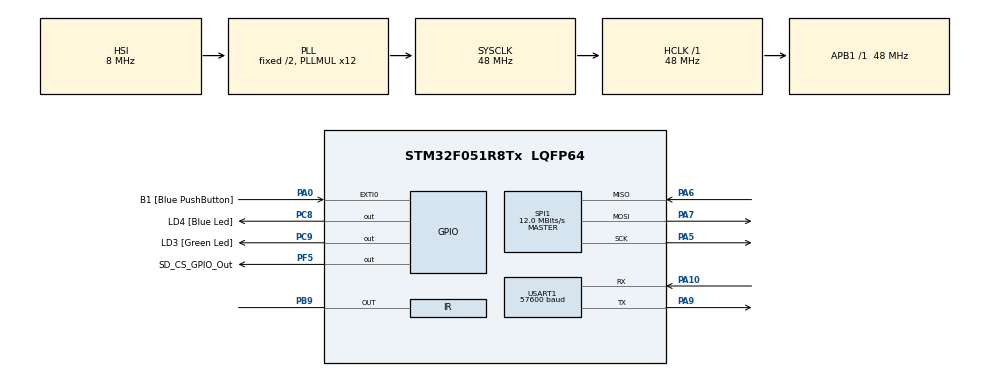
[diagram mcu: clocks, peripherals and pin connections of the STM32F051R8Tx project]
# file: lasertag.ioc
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Dma.Request0=USART1_RX
Dma.Request1=USART1_TX
Dma.USART1_RX.0.DMA_Remap=DMA_REMAP_USART1_RX_DMA_CH5
Dma.USART1_RX.0.Direction=DMA_PERIPH_TO_MEMORY
Dma.USART1_RX.0.Instance=DMA1_Channel5
Dma.USART1_RX.0.MemDataAlignment=DMA_MDATAALIGN_BYTE
Dma.USART1_RX.0.MemInc=DMA_MINC_ENABLE
Dma.USART1_RX.0.Mode=DMA_CIRCULAR
Dma.USART1_RX.0.PeriphDataAlignment=DMA_PDATAALIGN_BYTE
Dma.USART1_RX.0.PeriphInc=DMA_PINC_DISABLE
Dma.USART1_RX.0.Priority=DMA_PRIORITY_HIGH
Dma.USART1_TX.1.DMA_Remap=DMA_REMAP_USART1_TX_DMA_CH4
Dma.USART1_TX.1.Direction=DMA_MEMORY_TO_PERIPH
Dma.USART1_TX.1.Instance=DMA1_Channel4
Dma.USART1_TX.1.MemDataAlignment=DMA_MDATAALIGN_BYTE
Dma.USART1_TX.1.MemInc=DMA_MINC_ENABLE
Dma.USART1_TX.1.Mode=DMA_NORMAL
Dma.USART1_TX.1.PeriphDataAlignment=DMA_PDATAALIGN_BYTE
Dma.USART1_TX.1.PeriphInc=DMA_PINC_DISABLE
Dma.USART1_TX.1.Priority=DMA_PRIORITY_HIGH
FREERTOS.Tasks01=defaultTask,0,128,StartDefaultTask,Default
Mcu.Family=STM32F0
Mcu.Name=STM32F051R8Tx
Mcu.Package=LQFP64
NVIC.DMA1_Channel4_5_IRQn=true\:3\:0\:false\:false\:true
NVIC.SPI1_IRQn=true\:3\:0\:false\:false\:true
NVIC.TIM6_DAC_IRQn=true\:0\:0\:false\:false\:true
NVIC.TimeBase=TIM6_DAC_IRQn
NVIC.TimeBaseIP=TIM6
NVIC.USART1_IRQn=true\:3\:0\:false\:false\:true
PA0.GPIO_Label=B1 [Blue PushButton]
PA0.GPIO_ModeDefaultEXTI=GPIO_MODE_EVT_RISING
PA0.Signal=GPXTI0
PA10.Mode=Asynchronous
PA10.Signal=USART1_RX
PA13.GPIO_Label=SWDIO
PA13.Signal=SYS_SWDIO
PA14.GPIO_Label=SWCLK
PA14.Signal=SYS_SWCLK
PA5.Mode=Full_Duplex_Master
PA5.Signal=SPI1_SCK
PA6.Mode=Full_Duplex_Master
PA6.Signal=SPI1_MISO
PA7.Mode=Full_Duplex_Master
PA7.Signal=SPI1_MOSI
PA9.Mode=Asynchronous
PA9.Signal=USART1_TX
PB9.Mode=INFRARED
PB9.Signal=IR_OUT
PC8.GPIO_Label=LD4 [Blue Led]
PC8.Signal=GPIO_Output
PC9.GPIO_Label=LD3 [Green Led]
PC9.Signal=GPIO_Output
PF5.GPIO_Label=SD_CS_GPIO_Out
PF5.Signal=GPIO_Output
ProjectManager.HeapSize=0x200
ProjectManager.StackSize=0x400
ProjectManager.TargetToolchain=MDK-ARM V5
RCC.AHBFreq_Value=48000000
RCC.APB1Freq_Value=48000000
RCC.APB1TimFreq_Value=48000000
RCC.HCLKFreq_Value=48000000
RCC.PLLMUL=RCC_PLL_MUL12
RCC.SYSCLKFreq_VALUE=48000000
RCC.SYSCLKSource=RCC_SYSCLKSOURCE_PLLCLK
SPI1.BaudRatePrescaler=SPI_BAUDRATEPRESCALER_4
SPI1.CLKPhase=SPI_PHASE_1EDGE
SPI1.CLKPolarity=SPI_POLARITY_LOW
SPI1.CalculateBaudRate=12.0 MBits/s
SPI1.DataSize=SPI_DATASIZE_8BIT
SPI1.Mode=SPI_MODE_MASTER
SPI1.NSSPMode=SPI_NSS_PULSE_DISABLE
USART1.BaudRate=57600
VP_FREERTOS_VS_ENABLE.Mode=Enabled
VP_SYS_VS_tim6.Mode=TIM6
VP_TIM16_VS_ClockSourceINT.Mode=Enable_Timer
VP_TIM16_VS_no_output1.Mode=Output Compare1 No Output
VP_TIM17_VS_ClockSourceINT.Mode=Enable_Timer
VP_TIM17_VS_no_output1.Mode=Output Compare1 No Output
board=STM32F0DISCOVERY

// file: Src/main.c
/**
  ******************************************************************************
  * File Name          : main.c
  * Description        : Main program body
  ******************************************************************************
  *
  * COPYRIGHT(c) 2016 STMicroelectronics
  *
  * Redistribution and use in source and binary forms, with or without modification,
  * are permitted provided that the following conditions are met:
  *   1. Redistributions of source code must retain the above copyright notice,
  *      this list of conditions and the following disclaimer.
  *   2. Redistributions in binary form must reproduce the above copyright notice,
  *      this list of conditions and the following disclaimer in the documentation
  *      and/or other materials provided with the distribution.
  *   3. Neither the name of STMicroelectronics nor the names of its contributors
  *      may be used to endorse or promote products derived from this software
  *      without specific prior written permission.
  *
  * THIS SOFTWARE IS PROVIDED BY THE COPYRIGHT HOLDERS AND CONTRIBUTORS "AS IS"
  * AND ANY EXPRESS OR IMPLIED WARRANTIES, INCLUDING, BUT NOT LIMITED TO, THE
  * IMPLIED WARRANTIES OF MERCHANTABILITY AND FITNESS FOR A PARTICULAR PURPOSE ARE
  * DISCLAIMED. IN NO EVENT SHALL THE COPYRIGHT HOLDER OR CONTRIBUTORS BE LIABLE
  * FOR ANY DIRECT, INDIRECT, INCIDENTAL, SPECIAL, EXEMPLARY, OR CONSEQUENTIAL
  * DAMAGES (INCLUDING, BUT NOT LIMITED TO, PROCUREMENT OF SUBSTITUTE GOODS OR
  * SERVICES; LOSS OF USE, DATA, OR PROFITS; OR BUSINESS INTERRUPTION) HOWEVER
  * CAUSED AND ON ANY THEORY OF LIABILITY, WHETHER IN CONTRACT, STRICT LIABILITY,
  * OR TORT (INCLUDING NEGLIGENCE OR OTHERWISE) ARISING IN ANY WAY OUT OF THE USE
  * OF THIS SOFTWARE, EVEN IF ADVISED OF THE POSSIBILITY OF SUCH DAMAGE.
  *
  ******************************************************************************
  */
#include "stm32f0xx_hal.h"
#include "cmsis_os.h"
#include "dma.h"
#include "irtim.h"
#include "spi.h"
#include "tim.h"
#include "usart.h"
#include "gpio.h"

/* USER CODE BEGIN Includes */
#include "main.h"

/* USER CODE END Includes */

/* USER CODE BEGIN PV */
/* Private variables ---------------------------------------------------------*/

/* USER CODE END PV */

void SystemClock_Config(void);
void MX_FREERTOS_Init(void);

/* USER CODE BEGIN PFP */
/* Private function prototypes -----------------------------------------------*/

/* USER CODE END PFP */

int main(void)
{

  /* MCU Configuration----------------------------------------------------------*/

  /* Reset of all peripherals, Initializes the Flash interface and the Systick. */
  HAL_Init();

  /* Configure the system clock */
  SystemClock_Config();

  /* Initialize all configured peripherals */
  MX_GPIO_Init();
  MX_DMA_Init();
  MX_USART1_UART_Init();
  MX_SPI1_Init();
  MX_IRTIM_Init();
  MX_TIM16_Init();
  MX_TIM17_Init();

  /* USER CODE BEGIN 2 */

	BSP_SERIAL_FLASH_Init();
	LASERTAG_BOARD_Init();

  //uint32_t FlashId;
	uint8_t TxTemp[16] = "TEST";
	uint8_t RXTemp[16];

	BSP_SERIAL_FLASH_EraseSector(0x000000);
	BSP_SERIAL_FLASH_WritePage(0x000000, (uint8_t*) TxTemp, 16);
	BSP_SERIAL_FLASH_ReadData(0x000000, (uint8_t*) RXTemp, 16);
	HAL_Delay(1500);

	BSP_SERIAL_FLASH_ReadData(0x000002, (uint8_t*) RXTemp, 16);
  /* USER CODE END 2 */

  /* Call init function for freertos objects (in freertos.c) */
  MX_FREERTOS_Init();

  /* Start scheduler */
  osKernelStart();

  /* We should never get here as control is now taken by the scheduler */

  /* Infinite loop */
  while (1)
  {

  /* USER CODE BEGIN 3 */
		HAL_GPIO_TogglePin(LD4_GPIO_Port, LD4_Pin); //blue

		HAL_Delay(1500);

  }
  /* USER CODE END 3 */

}

/** System Clock Configuration
*/
void SystemClock_Config(void)
{

  RCC_OscInitTypeDef RCC_OscInitStruct;
  RCC_ClkInitTypeDef RCC_ClkInitStruct;
  RCC_PeriphCLKInitTypeDef PeriphClkInit;

  RCC_OscInitStruct.OscillatorType = RCC_OSCILLATORTYPE_HSI;
  RCC_OscInitStruct.HSIState = RCC_HSI_ON;
  RCC_OscInitStruct.HSICalibrationValue = 16;
  RCC_OscInitStruct.PLL.PLLState = RCC_PLL_ON;
  RCC_OscInitStruct.PLL.PLLSource = RCC_PLLSOURCE_HSI;
  RCC_OscInitStruct.PLL.PLLMUL = RCC_PLL_MUL12;
  RCC_OscInitStruct.PLL.PREDIV = RCC_PREDIV_DIV1;
  HAL_RCC_OscConfig(&RCC_OscInitStruct);

  RCC_ClkInitStruct.ClockType = RCC_CLOCKTYPE_HCLK|RCC_CLOCKTYPE_SYSCLK
                              |RCC_CLOCKTYPE_PCLK1;
  RCC_ClkInitStruct.SYSCLKSource = RCC_SYSCLKSOURCE_PLLCLK;
  RCC_ClkInitStruct.AHBCLKDivider = RCC_SYSCLK_DIV1;
  RCC_ClkInitStruct.APB1CLKDivider = RCC_HCLK_DIV1;
  HAL_RCC_ClockConfig(&RCC_ClkInitStruct, FLASH_LATENCY_1);

  PeriphClkInit.PeriphClockSelection = RCC_PERIPHCLK_USART1;
  PeriphClkInit.Usart1ClockSelection = RCC_USART1CLKSOURCE_PCLK1;
  HAL_RCCEx_PeriphCLKConfig(&PeriphClkInit);

  HAL_SYSTICK_Config(HAL_RCC_GetHCLKFreq()/1000);

  HAL_SYSTICK_CLKSourceConfig(SYSTICK_CLKSOURCE_HCLK);

  /* SysTick_IRQn interrupt configuration */
  HAL_NVIC_SetPriority(SysTick_IRQn, 3, 0);
}

/************************ (C) COPYRIGHT STMicroelectronics *****END OF FILE****/
